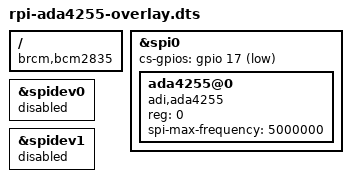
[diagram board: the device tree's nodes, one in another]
// SPDX-License-Identifier: GPL-2.0

/dts-v1/;
/plugin/;

#include <dt-bindings/gpio/gpio.h>
#include <dt-bindings/interrupt-controller/irq.h>

/ {
	compatible = "brcm,bcm2835", "brcm,bcm2711";
};

&spi0 {
	cs-gpios = <&gpio 17 GPIO_ACTIVE_LOW>;
	status = "okay";

	ada4255@0 {
		compatible = "adi,ada4255";
		reg = <0>;

		spi-max-frequency = <5000000>;
	};
};

&spidev0 {
	status = "disabled";
};

&spidev1 {
	status = "disabled";
};
